AUTOSAR XML (schema 00046)
package /ButtonManager_SWC_1_package
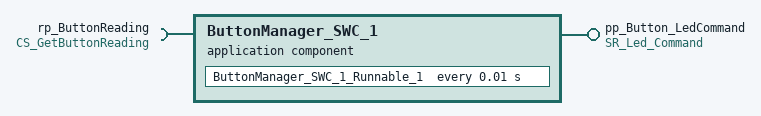
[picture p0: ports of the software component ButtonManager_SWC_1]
  application sw component type ButtonManager_SWC_1
    provide port pp_Button_LedCommand: provided-com-specs=nonqueued-sender-com-spec={data-element=SR_Led_Command_Element_1, init-value=SR_Led_Command_Element_1:0}, provided-interface=SR_Led_Command
    require port rp_ButtonReading: required-com-specs=[CS_GetButtonReading_Operation_1, CS_GetButtonReading_Operation_2], required-interface=CS_GetButtonReading
    behavior ButtonManager_SWC_1_internal_behavior
      timing event Periodic_Event_1_event: start-on-event=ButtonManager_SWC_1_Runnable_1, period=0.01
      runnable ButtonManager_SWC_1_Runnable_1
        data-send-points:
          access ButtonManager_SWC_1_Runnable_1_pp_Button_LedCommand_SR_Led_Command_Element_1: accessed-variable=pp_Button_LedCommand.SR_Led_Command_Element_1
        sync call ButtonManager_SWC_1_Runnable_1_rp_ButtonReading_CS_GetButtonReading_Operation_1: operation=rp_ButtonReading.CS_GetButtonReading_Operation_1
        sync call ButtonManager_SWC_1_Runnable_1_rp_ButtonReading_CS_GetButtonReading_Operation_2: operation=rp_ButtonReading.CS_GetButtonReading_Operation_2
